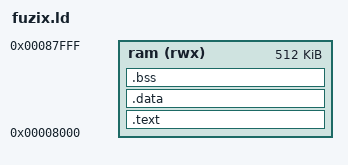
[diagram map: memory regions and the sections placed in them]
OUTPUT_ARCH(ns32k)

SEARCH_DIR(.)

MEMORY
{
  ram (rwx) : ORIGIN = 0x8000, LENGTH = 0x80000
}

/*
 * stick everything in ram (of course)
 */
SECTIONS
{
  .text :
  {
    CREATE_OBJECT_SYMBOLS
    *(.text .text.*)

    . = ALIGN(0x4);

    *(.rodata .rodata.*)

    . = ALIGN(0x4);
    _etext = .;
    *(.lit)
  } > ram

  .data :
  {
    *(.got.plt) *(.got)
    *(.shdata)
    *(.data .data.*)
    _edata = .;
  } > ram

  .bss :
  {
    . = ALIGN(0x4);
    __bss_start = . ;
    *(.shbss)
    *(.bss .bss.*)
    *(COMMON)
    _end =  ALIGN (0x8);
    __end = _end;
  } > ram

  .stab 0 (NOLOAD) :
  {
    *(.stab)
  }

  .stabstr 0 (NOLOAD) :
  {
    *(.stabstr)
  }
}
